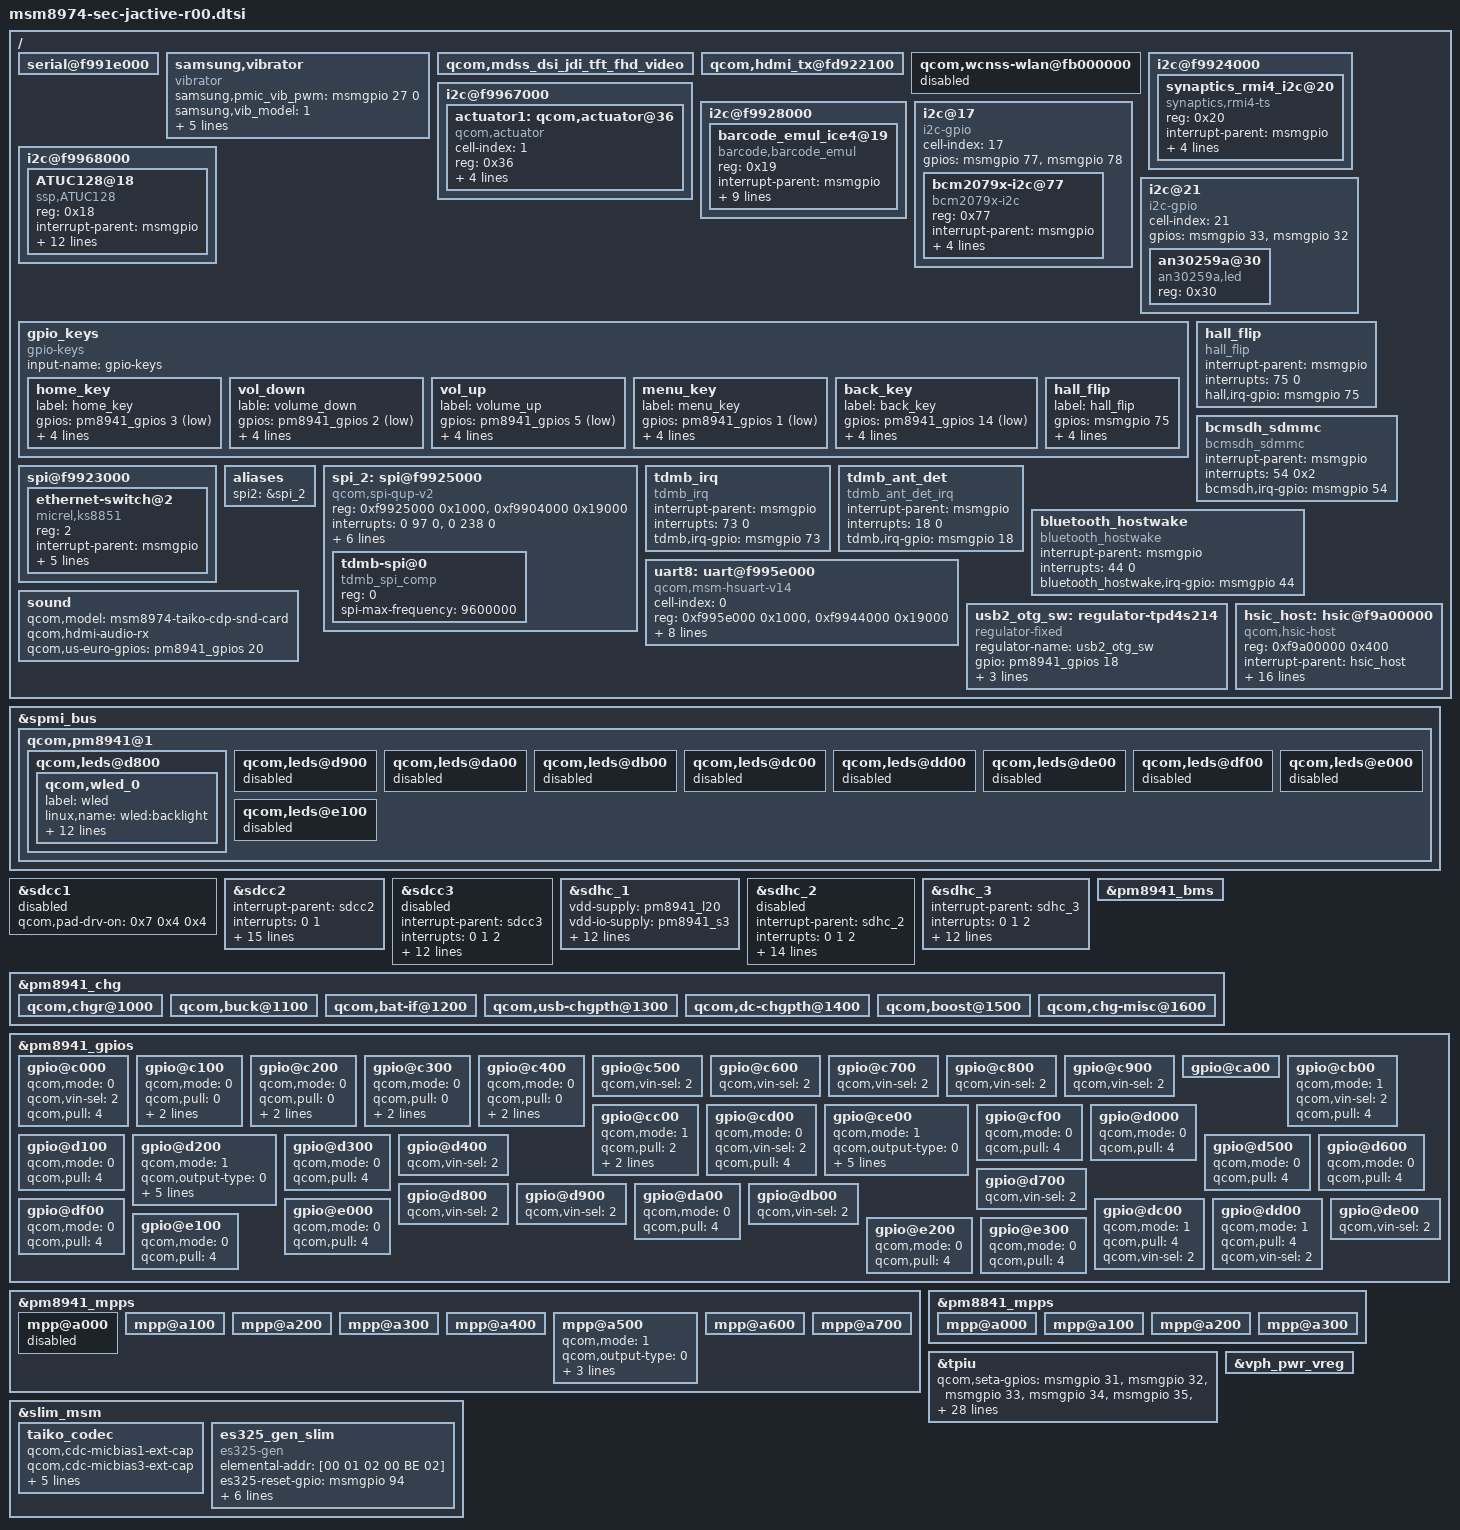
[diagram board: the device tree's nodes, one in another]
/* Copyright (c) 2012-2013, The Linux Foundation. All rights reserved.
 *
 * This program is free software; you can redistribute it and/or modify
 * it under the terms of the GNU General Public License version 2 and
 * only version 2 as published by the Free Software Foundation.
 *
 * This program is distributed in the hope that it will be useful,
 * but WITHOUT ANY WARRANTY; without even the implied warranty of
 * MERCHANTABILITY or FITNESS FOR A PARTICULAR PURPOSE.  See the
 * GNU General Public License for more details.
 */

/include/ "dsi_panel_jdi_tft_fhd_video.dtsi"
/include/ "msm8974-leds.dtsi"
/include/ "msm8974-camera-sensor-cdp-mtp.dtsi"
/include/ "msm8974-max77803-jactive-r00.dtsi"
/include/ "msm8974-sii8240_mhl-jactive-r00.dtsi"

/ {
	serial@f991e000 {
		status = "ok";
	};

	samsung,vibrator {
		compatible = "vibrator";
		samsung,pmic_vib_pwm = <&msmgpio 27 0>;
		samsung,vib_model = <1>;
		samsung,pmic_vib_en = <0>;
		samsung,pmic_haptic_pwr_en = <0>;
		samsung,is_pmic_vib_pwm = <0>;
		samsung,pwm_period_us = <40>;
		samsung,duty_us = <36>;
		status = "ok";
	};

	qcom,mdss_dsi_jdi_tft_fhd_video {
		status = "ok";
	};

	qcom,hdmi_tx@fd922100 {
		status = "ok";
	};

	qcom,wcnss-wlan@fb000000 {
		status = "disabled";
	};

	i2c@f9924000 {
		synaptics_rmi4_i2c@20 {
			compatible = "synaptics,rmi4-ts";
			reg = <0x20>;
			interrupt-parent = <&msmgpio>;
			interrupts = <80 0>;
			synaptics,tsppwr_en = <&pm8941_gpios 9 0x1>;
			synaptics,irq-gpio = <&msmgpio 80 0x00>;
			synaptics,i2c-pull-up = <1>;
		};
	};
	
	i2c@f9967000 {
		actuator1: qcom,actuator@36 {
		compatible = "qcom,actuator";
		cell-index = <1>;
		reg = <0x36>;
			gpios = <&msmgpio 83 0>,
				<&msmgpio 84 0>;
			qcom,gpio-req-tbl-num = <0 1>;
			qcom,gpio-req-tbl-flags = <1 1>;
			qcom,gpio-req-tbl-label = "I2C_DATA0",
						  "I2C_CLK0";
		};
	};

	i2c@f9928000 {
		barcode_emul_ice4@19 {
			compatible = "barcode,barcode_emul";
			reg = <0x19>;
			interrupt-parent = <&msmgpio>;
			interrupts = <64 0>;
			barcode,irda_en = <&pm8941_gpios 04 0x1>;
			barcode,cresetb = <&msmgpio 57 0x00>;
			barcode,reset_n = <&msmgpio 58 0x00>;
			barcode,cdone = <&msmgpio 53 0x00>;
			barcode,scl-gpio = <&msmgpio 30 0x00>;
			barcode,sda-gpio = <&msmgpio 29 0x00>;
			barcode,irq-gpio = <&msmgpio 64 0x00>;
			barcode,i2c-pull-up = <1>;
		};
	};

	i2c@17{
		cell-index = <17>;
		compatible = "i2c-gpio";
		gpios = <&msmgpio 77 0
			 &msmgpio 78 0
			>;
		bcm2079x-i2c@77{
			compatible = "bcm2079x-i2c";
			reg = <0x77>;
			interrupt-parent = <&msmgpio>;
			interrupts = <59 0>;
			bcm2079x-i2c,irq-gpio = <&msmgpio 59 0x00>;
			bcm2079x-i2c,en-gpio = <&pm8941_gpios 13 0x1>;
			bcm2079x-i2c,wake-gpio = <&msmgpio 61 0x00>;
		};
	};

	i2c@f9968000 {
		ATUC128@18{
			compatible = "ssp,ATUC128";
			reg = <0x18>;
			interrupt-parent = <&msmgpio>;
			interrupts = <74 0>;
			hub_vreg-supply = <&pm8941_lvs1>;
			psns_vreg-supply = <&pm8941_l18>;
			ssp,mcu_int1-gpio = <&msmgpio 74 0x00>;
			ssp,mcu_int2-gpio = <&msmgpio 86 0x00>;
			ssp,ap_int-gpio = <&msmgpio 89 0x00>;
			ssp,rst-gpio = <&msmgpio 50 0x00>;
			ssp,chg-gpio = <&msmgpio 91 0x00>;
			ssp,acc-position = <3>;
			ssp,mag-position = <5>;
			ssp,sns-combination = <1>;
			ssp,ap-rev=<4>;
			};
	};


	i2c@21 {
		cell-index = <21>;
		compatible = "i2c-gpio";
		gpios = <&msmgpio 33 0 /* sda */
		&msmgpio 32 0 /* scl */
		>;

		an30259a@30 {
			compatible = "an30259a,led";
			reg = <0x30>;
		};
	};

	gpio_keys {
		compatible = "gpio-keys";
		input-name = "gpio-keys";

		home_key {
			label = "home_key";
			gpios = <&pm8941_gpios 3 0x1>;
			linux,input-type = <1>;
			linux,code = <102>;
			gpio-key,wakeup;
			debounce-interval = <15>;
		};

		vol_down {
			lable = "volume_down";
			gpios = <&pm8941_gpios 2 0x1>;
			linux,input-type = <1>;
			linux,code = <114>;
			gpio-key,wakeup;
			debounce-interval = <15>;
		};

		vol_up {
			label = "volume_up";
			gpios = <&pm8941_gpios 5 0x1>;
			linux,input-type = <1>;
			linux,code = <115>;
			gpio-key,wakeup;
			debounce-interval = <15>;
		};

		menu_key {
			label = "menu_key";
			gpios = <&pm8941_gpios 1 0x1>;
			linux,input-type = <1>;
			linux,code = <139>;
			gpio-key,wakeup;
			debounce-interval = <15>;
		};

		back_key {
			label = "back_key";
			gpios = <&pm8941_gpios 14 0x1>;
			linux,input-type = <1>;
			linux,code = <158>;
			gpio-key,wakeup;
			debounce-interval = <15>;
		};

		hall_flip {
			label = "hall_flip";
			gpios = <&msmgpio 75 0>;
			linux,input-type = <1>;
			linux,code = <0x15>;
			gpio-key,wakeup;
			debounce-interval = <15>;
		};
	};

	hall_flip{
		compatible = "hall_flip";
		interrupt-parent = <&msmgpio>;
		interrupts = <75 0>;
		hall,irq-gpio = <&msmgpio 75 0x00>;
	};

	bcmsdh_sdmmc{
		compatible = "bcmsdh_sdmmc";
		interrupt-parent = <&msmgpio>;
		interrupts = <54 0x2>;
		bcmsdh,irq-gpio = <&msmgpio 54 0x00>;
	};

	spi@f9923000 {
		ethernet-switch@2 {
			compatible = "micrel,ks8851";
			reg = <2>;
			interrupt-parent = <&msmgpio>;
			interrupts = <94 0>;
			spi-max-frequency = <4800000>;
			rst-gpio = <&pm8941_mpps 6 0>;
			vdd-io-supply = <&spi_eth_vreg>;
			vdd-phy-supply = <&spi_eth_vreg>;
		};
	};

	aliases {
		spi2 = &spi_2;
	};
	spi_2: spi@f9925000 {
		compatible = "qcom,spi-qup-v2";
		reg = <0xf9925000 0x1000>, <0xf9904000 0x19000>;
		reg-names = "spi_physical", "spi_bam_physical";
		interrupts = <0 97 0>, <0 238 0>;
		interrupt-names = "spi_irq", "spi_bam_irq";
		qcom,use-bam;
		qcom,bam-consumer-pipe-index = <16>;
		qcom,bam-producer-pipe-index = <17>;
		spi-max-frequency = <19200000>;
		#address-cells = <1>;
		#size-cells = <0>;
		gpios = <&msmgpio 11 0>, /* CLK  */
			<&msmgpio 9 0>, /* MISO */
			<&msmgpio 8 0>; /* MOSI */
		cs-gpios = <&msmgpio 10 0>;
		tdmb-spi@0 {
			compatible = "tdmb_spi_comp";
			reg = <0>;
			spi-max-frequency = <9600000>;
		};
	};

	tdmb_irq{
		compatible = "tdmb_irq";
		interrupt-parent = <&msmgpio>;
		interrupts = <73 0>;
		tdmb,irq-gpio = <&msmgpio 73 0x00>;
	};

	tdmb_ant_det{
		compatible = "tdmb_ant_det_irq";
		interrupt-parent = <&msmgpio>;
		interrupts = <18 0>;
		tdmb,irq-gpio = <&msmgpio 18 0x00>;
	};

	bluetooth_hostwake{
		compatible = "bluetooth_hostwake";
		interrupt-parent = <&msmgpio>;
		interrupts = <44 0>;
		bluetooth_hostwake,irq-gpio = <&msmgpio 44 0x00>;
	};

	uart8: uart@f995e000 { /*BLSP #2, UART #8 */
		cell-index = <0>;
		compatible = "qcom,msm-hsuart-v14";
		status = "ok";
		reg = <0xf995e000 0x1000>,
		      <0xf9944000 0x19000>;
		reg-names = "core_mem", "bam_mem";

		interrupts = <0 114 0>, <0 239 0>;
		interrupt-names = "core_irq", "bam_irq";
		qcom,bam-tx-ep-pipe-index = <2>;
		qcom,bam-rx-ep-pipe-index = <3>;
		qcom,msm-bus,name = "uart8";
		qcom,msm-bus,num-cases = <2>;
		qcom,msm-bus,num-paths = <1>;
		qcom,msm-bus,vectors-KBps =
				<84 512 0 0>,
				<84 512 500 800>;
	};

	sound {
		qcom,model = "msm8974-taiko-cdp-snd-card";
		qcom,hdmi-audio-rx;
		qcom,us-euro-gpios = <&pm8941_gpios 20 0>;
	};

	usb2_otg_sw: regulator-tpd4s214 {
		compatible = "regulator-fixed";
		regulator-name = "usb2_otg_sw";
		gpio = <&pm8941_gpios 18 0>;
		parent-supply = <&pm8941_boost>;
		startup-delay-us = <17000>;
		enable-active-high;
	};

	hsic_host: hsic@f9a00000 {
		compatible = "qcom,hsic-host";
		reg = <0xf9a00000 0x400>;
		#address-cells = <0>;
		interrupt-parent = <&hsic_host>;
		interrupts = <0 1 2>;
		#interrupt-cells = <1>;
		interrupt-map-mask = <0xffffffff>;
		interrupt-map = <0 &intc 0 136 0
			1 &intc 0 148 0
			2 &msmgpio 144 0x8>;
		interrupt-names = "core_irq", "async_irq", "wakeup";
		HSIC_VDDCX-supply = <&pm8841_s2>;
		HSIC_GDSC-supply = <&gdsc_usb_hsic>;
		hsic,strobe-gpio = <&msmgpio 144 0x00>;
		hsic,data-gpio = <&msmgpio 145 0x00>;
		hsic,ignore-cal-pad-config;
		hsic,strobe-pad-offset = <0x2050>;
		hsic,data-pad-offset = <0x2054>;

		qcom,msm-bus,name = "hsic";
		qcom,msm-bus,num-cases = <2>;
		qcom,msm-bus,num-paths = <1>;
		qcom,msm-bus,vectors-KBps =
				<85 512 0 0>,
				<85 512 40000 160000>;
        };

	/* wlan0: qca,wlan {
		compatible = "qca,ar6004-hsic";
		qcom,msm-bus,name = "wlan";
		qcom,msm-bus,num-cases = <5>;
		qcom,msm-bus,active-only = <0>;
		qcom,msm-bus,num-paths = <1>;
		qcom,msm-bus,vectors-KBps =
				<85 512 0 0>,
				<85 512 40000 160000>,
				<85 512 40000 320000>,
				<85 512 40000 480000>,
				<85 512 40000 640000>;
	};*/
};

&spmi_bus {
	qcom,pm8941@1 {
		qcom,leds@d800 {
			status = "okay";
			qcom,wled_0 {
				label = "wled";
				linux,name = "wled:backlight";
				linux,default-trigger = "bkl-trigger";
				qcom,cs-out-en;
				qcom,op-fdbck = <1>;
				qcom,default-state = "off";
				qcom,max-current = <25>;
				qcom,ctrl-delay-us = <0>;
				qcom,boost-curr-lim = <3>;
				qcom,cp-sel = <0>;
				qcom,switch-freq = <2>;
				qcom,ovp-val = <2>;
				qcom,num-strings = <1>;
				qcom,id = <0>;
			};
		};

		qcom,leds@d900 {
			status = "disabled";
		};

		qcom,leds@da00 {
			status = "disabled";
		};

		qcom,leds@db00 {
			status = "disabled";
		};

		qcom,leds@dc00 {
			status = "disabled";
		};

		qcom,leds@dd00 {
			status = "disabled";
		};

		qcom,leds@de00 {
			status = "disabled";
		};

		qcom,leds@df00 {
			status = "disabled";
		};

		qcom,leds@e000 {
			status = "disabled";
		};

		qcom,leds@e100 {
			status = "disabled";
		};
	};
};

&sdcc1 {
       status = "disabled";
};

&sdcc2 {
	#address-cells = <0>;
	interrupt-parent = <&sdcc2>;
	interrupts = <0 1>;
	#interrupt-cells = <1>;
	interrupt-map-mask = <0xffffffff>;
	interrupt-map = <0 &intc 0 125 0
					1 &intc 0 220 0>;
	interrupt-names = "core_irq", "bam_irq";
	//cd-gpios = <&msmgpio 62 0x1>;
	wp-gpios = <&pm8941_gpios 29 0x1>;

	//fix sleep power rail breakdown
	vdd-supply = <&pm8941_l6>;
	vdd-io-supply = <&pm8941_l6>;

	qcom,vdd-voltage-level = <1800000 1800000>;
	qcom,vdd-current-level = <2000 16000>;

	qcom,vdd-io-voltage-level = <1800000 1800000>;
	qcom,vdd-io-current-level = <2000 16000>;

	qcom,current-limit = <16000>;

	qcom,clk-rates = <400000 20000000 25000000 50000000 100000000 200000000>;
	qcom,sup-voltages = <2950 2950>;
	//qcom,vdd-always-on;
	//qcom,vdd-lpm-sup;

	status-cb = <2>;
	status = "ok";
};

&sdcc3 {
	#address-cells = <0>;
	interrupt-parent = <&sdcc3>;
	interrupts = <0 1 2>;
	#interrupt-cells = <1>;
	interrupt-map-mask = <0xffffffff>;
	interrupt-map = <0 &intc 0 127 0
			1 &intc 0 223 0
			2 &msmgpio 62 0x3>;
	interrupt-names = "core_irq", "bam_irq", "status_irq";

	vdd-supply = <&pm8941_l21>;
	vdd-io-supply = <&pm8941_l13>;
	qcom,vdd-voltage-level = <2950000 2950000>;
	qcom,vdd-current-level = <9000 800000>;
	qcom,vdd-io-voltage-level = <1800000 1800000>;
	qcom,vdd-io-current-level = <6 22000>;
	qcom,sup-voltages = <2950 2950>;

	cd-gpios = <&msmgpio 62 0x1>;
	wp-gpios = <&pm8941_gpios 29 0x1>;
//	ls-gpios = <&pm8941_gpios 1 0x1>;

	status = "disabled";
};

&sdhc_1 {
	vdd-supply = <&pm8941_l20>;
	vdd-io-supply = <&pm8941_s3>;

	qcom,vdd-always-on;
	qcom,vdd-lpm-sup;
	qcom,vdd-voltage-level = <2950000 2950000>;
	qcom,vdd-current-level = <800 500000>;

	qcom,vdd-io-always-on;
	qcom,vdd-io-voltage-level = <1800000 1800000>;
	qcom,vdd-io-current-level = <250 154000>;

	qcom,pad-pull-on = <0x0 0x3 0x3>; /* no-pull, pull-up, pull-up */
	qcom,pad-pull-off = <0x0 0x3 0x3>; /* no-pull, pull-up, pull-up */
	qcom,pad-drv-on = <0x7 0x4 0x4>; /* 16mA, 10mA, 10mA */
	qcom,pad-drv-off = <0x0 0x0 0x0>; /* 2mA, 2mA, 2mA */

	qcom,nonremovable;
	status = "ok";
};

&sdhc_2 {
	#address-cells = <0>;
	interrupt-parent = <&sdhc_2>;
	interrupts = <0 1 2>;
	#interrupt-cells = <1>;
	interrupt-map-mask = <0xffffffff>;
	interrupt-map = <0 &intc 0 125 0
			1 &intc 0 221 0
			2 &msmgpio 62 0x3>;
	interrupt-names = "hc_irq", "pwr_irq", "status_irq";
	cd-gpios = <&msmgpio 62 0x1>;

	vdd-supply = <&pm8941_l21>;
	vdd-io-supply = <&pm8941_l13>;

	qcom,vdd-voltage-level = <2950000 2950000>;
	qcom,vdd-current-level = <9000 800000>;

	qcom,vdd-io-voltage-level = <1800000 2950000>;
	qcom,vdd-io-current-level = <6 22000>;

	qcom,pad-pull-on = <0x0 0x3 0x3>; /* no-pull, pull-up, pull-up */
	qcom,pad-pull-off = <0x0 0x3 0x3>; /* no-pull, pull-up, pull-up */
	qcom,pad-drv-on = <0x7 0x4 0x4>; /* 16mA, 10mA, 10mA */
	qcom,pad-drv-off = <0x0 0x0 0x0>; /* 2mA, 2mA, 2mA */
	status = "disable";
};

&sdhc_3 {
	#address-cells = <0>;
	interrupt-parent = <&sdhc_3>;
	interrupts = <0 1 2>;
	#interrupt-cells = <1>;
	interrupt-map-mask = <0xffffffff>;
	interrupt-map = <0 &intc 0 127 0
			1 &intc 0 224 0
			2 &msmgpio 62 0x3>;
	interrupt-names = "hc_irq", "pwr_irq", "status_irq";

	vdd-supply = <&pm8941_l21>;
	vdd-io-supply = <&pm8941_l13>;
	qcom,vdd-voltage-level = <2950000 2950000>;
	qcom,vdd-current-level = <9000 800000>;
	qcom,vdd-io-voltage-level = <1800000 1800000>;
	qcom,vdd-io-current-level = <6 22000>;
	qcom,sup-voltages = <2950 2950>;

	cd-gpios = <&msmgpio 62 0x1>;
	wp-gpios = <&pm8941_gpios 29 0x1>;
//	ls-gpios = <&pm8941_gpios 1 0x1>;

	status = "ok";
};

/* Drive strength recommendations for clock line from hardware team is 10 mA.
 * But since the driver has been been using the below values from the start
 * without any problems, continue to use those.
 */
&sdcc1 {
	qcom,pad-drv-on = <0x7 0x4 0x4>; /* 16mA, 10mA, 10mA */
};

&sdcc2 {
	qcom,pad-drv-on = <0x1 0x4 0x4>; /* 4mA, 10mA, 10mA */
};

&sdhc_1 {
	qcom,pad-drv-on = <0x7 0x4 0x4>; /* 16mA, 10mA, 10mA */
};

&sdhc_2 {
	qcom,pad-drv-on = <0x7 0x4 0x4>; /* 16mA, 10mA, 10mA */
};

&pm8941_bms {
	status = "ok";
};

&pm8941_chg {
	status = "ok";

	qcom,chgr@1000 {
		status = "ok";
	};

	qcom,buck@1100 {
		status = "ok";
	};

	qcom,bat-if@1200 {
		status = "ok";
	};

	qcom,usb-chgpth@1300 {
		status = "ok";
	};

	qcom,dc-chgpth@1400 {
		status = "ok";
	};

	qcom,boost@1500 {
		status = "ok";
	};

	qcom,chg-misc@1600 {
		status = "ok";
	};
};

&pm8941_gpios {
	gpio@c000 { /* GPIO 1 */
		qcom,mode = <0>;
		qcom,vin-sel = <2>;
		qcom,pull = <4>;
	};

	gpio@c100 { /* GPIO 2 */
		qcom,mode = <0>;
		qcom,pull = <0>;
		qcom,vin-sel = <2>;
		qcom,select = <0>;
	};

	gpio@c200 { /* GPIO 3 */
		qcom,mode = <0>;
		qcom,pull = <0>;
		qcom,vin-sel = <2>;
		qcom,src-sel = <0>;
	};

	gpio@c300 { /* GPIO 4 */
		qcom,mode = <0>;
		qcom,pull = <0>;
		qcom,vin-sel = <2>;
		qcom,src-sel = <0>;
	};

	gpio@c400 { /* GPIO 5 */
		qcom,mode = <0>;
		qcom,pull = <0>;
		qcom,vin-sel = <2>;
		qcom,src-sel = <0>;
	};

	gpio@c500 { /* GPIO 6 */
                qcom,vin-sel = <2>;
	};

	gpio@c600 { /* GPIO 7 */
                qcom,vin-sel = <2>;
	};

	gpio@c700 { /* GPIO 8 */
                qcom,vin-sel = <2>;
	};

	gpio@c800 { /* GPIO 9 */
                qcom,vin-sel = <2>;
	};

	gpio@c900 { /* GPIO 10 */
                qcom,vin-sel = <2>;
	};

	gpio@ca00 { /* GPIO 11 */
	};

	gpio@cb00 { /* GPIO 12 */
		qcom,mode = <1>;
                qcom,vin-sel = <2>;
		qcom,pull = <4>;
	};

	gpio@cc00 { /* GPIO 13 */
		qcom,mode = <1>;
		qcom,pull = <2>;
		qcom,vin-sel = <2>;
		qcom,src-sel = <0>;
	};

	gpio@cd00 { /* GPIO 14 */
		qcom,mode = <0>;
		qcom,vin-sel = <2>;
		qcom,pull = <4>;
	};

	gpio@ce00 { /* GPIO 15 */
		qcom,mode = <1>;
		qcom,output-type = <0>;
		qcom,pull = <5>;
		qcom,vin-sel = <2>;
		qcom,out-strength = <3>;
		qcom,src-sel = <2>;
		qcom,master-en = <1>;
	};

	gpio@cf00 { /* GPIO 16 */
		qcom,mode = <0>;
		qcom,pull = <4>;
	};

	gpio@d000 { /* GPIO 17 */
                qcom,mode = <0>;
                qcom,pull = <4>;
	};

	gpio@d100 { /* GPIO 18 */
		qcom,mode = <0>;
		qcom,pull = <4>;
	};

	gpio@d200 { /* GPIO 19 */
		qcom,mode = <1>;		/* QPNP_PIN_MODE_DIG_OUT */
		qcom,output-type = <0>;		/* QPNP_PIN_OUT_BUF_CMOS */
		qcom,pull = <5>;		/* QPNP_PIN_PULL_NO */
		qcom,vin-sel = <2>;		/* QPNP_PIN_VIN2 */
		qcom,out-strength = <2>;	/* QPNP_PIN_OUT_STRENGTH_MED */
		qcom,src-sel = <0>;		/* QPNP_PIN_SEL_FUNC_CONSTANT */
		qcom,master-en = <1>;
	};

	gpio@d300 { /* GPIO 20 */
	        qcom,mode = <0>;
                qcom,pull = <4>;
	};

	gpio@d400 { /* GPIO 21 */
                qcom,vin-sel = <2>;
	};

	gpio@d500 { /* GPIO 22 */
	        qcom,mode = <0>;
                qcom,pull = <4>;
	};

	gpio@d600 { /* GPIO 23 */
		qcom,mode = <0>;
		qcom,pull = <4>;
	};

	gpio@d700 { /* GPIO 24 */
                qcom,vin-sel = <2>;
	};

	gpio@d800 { /* GPIO 25 */
                qcom,vin-sel = <2>;
	};

	gpio@d900 { /* GPIO 26 */
                qcom,vin-sel = <2>;
	};

	gpio@da00 { /* GPIO 27 */
                qcom,mode = <0>;
                qcom,pull = <4>;
	};

	gpio@db00 { /* GPIO 28 */
                qcom,vin-sel = <2>;
	};

	gpio@dc00 { /* GPIO 29 */
		qcom,mode = <1>;
		qcom,pull = <4>;
		qcom,vin-sel = <2>;
	};

	gpio@dd00 { /* GPIO 30 */
		qcom,mode = <1>;
		qcom,pull = <4>;
		qcom,vin-sel = <2>;
	};

	gpio@de00 { /* GPIO 31 */
                qcom,vin-sel = <2>;
	};

	gpio@df00 { /* GPIO 32 */
                qcom,mode = <0>;
                qcom,pull = <4>;
	};

	gpio@e000 { /* GPIO 33 */
                qcom,mode = <0>;
                qcom,pull = <4>;
	};

	gpio@e100 { /* GPIO 34 */
                qcom,mode = <0>;
                qcom,pull = <4>;
	};

	gpio@e200 { /* GPIO 35 */
                qcom,mode = <0>;
                qcom,pull = <4>;
	};

	gpio@e300 { /* GPIO 36 */
                qcom,mode = <0>;
                qcom,pull = <4>;
	};
};

&pm8941_mpps {

	mpp@a000 { /* MPP 1 */
		status = "disabled";
	};

	mpp@a100 { /* MPP 2 */
	};

	mpp@a200 { /* MPP 3 */
	};

	mpp@a300 { /* MPP 4 */
	};

	mpp@a400 { /* MPP 5 */
	};

	mpp@a500 { /* MPP 6 */
		/* SPI_ETH_RST config */
		qcom,mode = <1>; /* DIG_OUT */
		qcom,output-type = <0>; /* CMOS */
		qcom,vin-sel = <2>; /* PM8941_S3 1.8V > 1.6V */
		qcom,src-sel = <0>; /* CONSTANT */
		qcom,master-en = <1>; /* ENABLE MPP */
	};

	mpp@a600 { /* MPP 7 */
	};

	mpp@a700 { /* MPP 8 */
	};
};

&pm8841_mpps {

	mpp@a000 { /* MPP 1 */
	};

	mpp@a100 { /* MPP 2 */
	};

	mpp@a200 { /* MPP 3 */
	};

	mpp@a300 { /* MPP 4 */
	};
};

/* CoreSight */
&tpiu {
	qcom,seta-gpios = <&msmgpio 31 0>,
			  <&msmgpio 32 0>,
			  <&msmgpio 33 0>,
			  <&msmgpio 34 0>,
			  <&msmgpio 35 0>,
			  <&msmgpio 36 0>,
			  <&msmgpio 37 0>,
			  <&msmgpio 38 0>,
			  <&msmgpio 39 0>,
			  <&msmgpio 40 0>,
			  <&msmgpio 41 0>,
			  <&msmgpio 42 0>,
			  <&msmgpio 43 0>,
			  <&msmgpio 44 0>,
			  <&msmgpio 45 0>,
			  <&msmgpio 46 0>,
			  <&msmgpio 47 0>,
			  <&msmgpio 48 0>;
	qcom,seta-gpios-func = <4 4 4 3 4 4 4 3 4 3 5 5 5 5 4 4 5 5>;
	qcom,seta-gpios-drv =  <7 7 7 7 7 7 7 7 7 7 7 7 7 7 7 7 7 7>;
	qcom,seta-gpios-pull = <0 0 0 0 0 0 0 0 0 0 0 0 0 0 0 0 0 0>;
	qcom,seta-gpios-dir =  <2 2 2 2 2 2 2 2 2 2 2 2 2 2 2 2 2 2>;

	qcom,setb-gpios = <&msmgpio 15 0>,
			  <&msmgpio 16 0>,
			  <&msmgpio 17 0>,
			  <&msmgpio 18 0>,
			  <&msmgpio 19 0>,
			  <&msmgpio 20 0>,
			  <&msmgpio 21 0>,
			  <&msmgpio 22 0>,
			  <&msmgpio 23 0>,
			  <&msmgpio 24 0>,
			  <&msmgpio 25 0>,
			  <&msmgpio 26 0>,
			  <&msmgpio 27 0>,
			  <&msmgpio 28 0>,
			  <&msmgpio 89 0>,
			  <&msmgpio 90 0>,
			  <&msmgpio 91 0>,
			  <&msmgpio 92 0>;
	qcom,setb-gpios-func = <2 2 2 2 5 5 5 5 6 6 6 7 7 5 2 3 3 3>;
	qcom,setb-gpios-drv =  <7 7 7 7 7 7 7 7 7 7 7 7 7 7 7 7 7 7>;
	qcom,setb-gpios-pull = <0 0 0 0 0 0 0 0 0 0 0 0 0 0 0 0 0 0>;
	qcom,setb-gpios-dir =  <2 2 2 2 2 2 2 2 2 2 2 2 2 2 2 2 2 2>;
};

&vph_pwr_vreg {
	status = "ok";
};

&slim_msm {
	taiko_codec {
		qcom,cdc-micbias1-ext-cap;
//		qcom,cdc-micbias2-ext-cap;
		qcom,cdc-micbias3-ext-cap;
		qcom,cdc-micbias4-ext-cap;
		
		/*
		 * Liquid has external spkrdrv supply. Give a dummy supply to
		 * make codec driver's happy.
		 */
		cdc-vdd-spkdrv-supply = <&vph_pwr_vreg>;
		qcom,cdc-vdd-spkdrv-voltage = <0 0>;
		qcom,cdc-vdd-spkdrv-current = <0>;

		qcom,cdc-on-demand-supplies = "cdc-vdd-spkdrv";
	};
	es325_gen_slim {
		compatible = "es325-gen";
		elemental-addr = [00 01 02 00 BE 02];
		
		es325-reset-gpio = <&msmgpio 94 0>;
		es325-wakeup-gpio = <&msmgpio 85 0>;
		
		es325-mclk-clk = <&pm8941_clkdiv1>;
		es325-mclk-clk-freq = <9600000>;
		
		es325-slim-ifd = "es325-ifd";
		es325-slim-ifd-elemental-addr = [00 00 02 00 BE 02];
	};
};
